# GIO register map
Vendor: Texas Instruments
Peripheral module from a debugger description file (folder ucd3138128).
Registers are 32-bit, access not given, no defined reset value unless marked. A register's access mark holds for its fields unless they carry their own. Offsets are as the file gives them; lines under a group give offsets from that group; [hi:lo] are bit positions; {n}, {i} and the like mark numbered series; 'fields as' and 'values as' point back to an identical list; <NAME> marks a mode.

## GIO
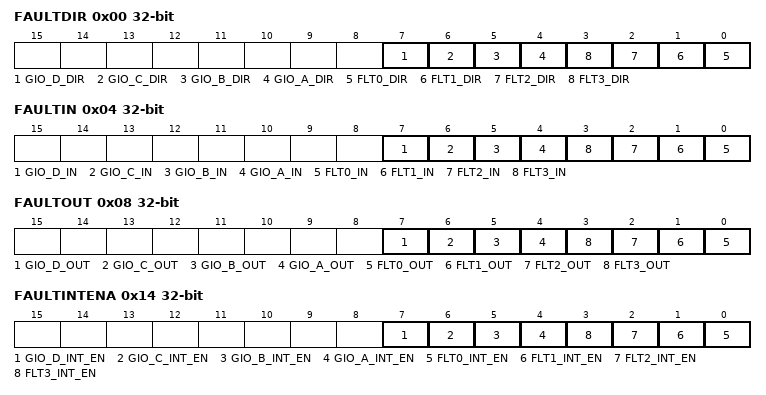
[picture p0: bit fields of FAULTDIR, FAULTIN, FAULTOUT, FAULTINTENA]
0x00 FAULTDIR — Fault Port Direction Register
  [7] GIO_D_DIR rw — GIO_D Pin Direction in GPIO Mode
  [6] GIO_C_DIR rw — GIO_C Pin Direction in GPIO Mode
  [5] GIO_B_DIR rw — GIO_B Pin Direction in GPIO Mode
  [4] GIO_A_DIR rw — GIO_A Pin Direction in GPIO Mode
  [n] FLT{n}_DIR rw (n=0..3) — FAULT[{n}] Pin Direction
0x04 FAULTIN — Fault Port Input Data
  [7] GIO_D_IN ro — GIO_D Input Value in GPIO Mode
  [6] GIO_C_IN ro — GIO_C Input Value in GPIO Mode
  [5] GIO_B_IN ro — GIO_B Input Value in GPIO Mode
  [4] GIO_A_IN ro — GIO_A Input Value in GPIO Mode
  [n] FLT{n}_IN ro (n=0..3) — FAULT[{n}] Input Value
0x08 FAULTOUT — Fault Port Output Data
  [7] GIO_D_OUT rw — GIO_D pin output data
  [6] GIO_C_OUT rw — GIO_C pin output data
  [5] GIO_B_OUT rw — GIO_B pin output data
  [4] GIO_A_OUT rw — GIO_A pin output data
  [n] FLT{n}_OUT rw (n=0..3) — FAULT[{n}] pin output data
0x14 FAULTINTENA — Fault Port Interrupt Enable Register
  [7] GIO_D_INT_EN rw — GIO_D pin interrupt enable
  [6] GIO_C_INT_EN rw — GIO_C pin interrupt enable
  [5] GIO_B_INT_EN rw — GIO_B pin interrupt enable
  [4] GIO_A_INT_EN rw — GIO_A pin interrupt enable
  [n] FLT{n}_INT_EN rw (n=0..3) — FAULT[{n}] pin interrupt enable
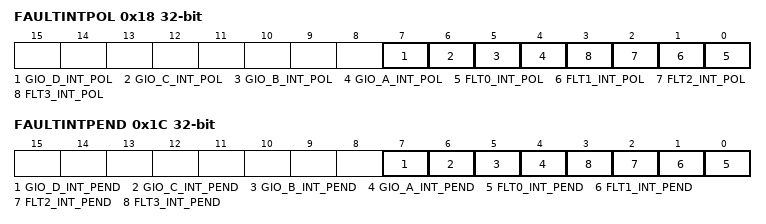
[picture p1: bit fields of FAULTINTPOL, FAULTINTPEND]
0x18 FAULTINTPOL — Fault Port Interrupt Polarity Register
  [7] GIO_D_INT_POL rw — GIO_D pin interrupt polarity
  [6] GIO_C_INT_POL rw — GIO_C pin interrupt polarity
  [5] GIO_B_INT_POL rw — GIO_B pin interrupt polarity
  [4] GIO_A_INT_POL rw — GIO_A pin interrupt polarity
  [n] FLT{n}_INT_POL rw (n=0..3) — FAULT[{n}] pin interrupt polarity
0x1C FAULTINTPEND — Fault Port Interrupt Pending Register
  [7] GIO_D_INT_PEND rw — GIO_D pin interrupt flag
  [6] GIO_C_INT_PEND rw — GIO_C pin interrupt flag
  [5] GIO_B_INT_PEND rw — GIO_B pin interrupt flag
  [4] GIO_A_INT_PEND rw — GIO_A pin interrupt flag
  [n] FLT{n}_INT_PEND rw (n=0..3) — FAULT[{n}] pin interrupt flag
0x20 EXTINTDIR — External Interrupt Direction Register
  [0] EXT_INT_DIR rw — External Interrupt Pin Direction
0x24 EXTINTIN — External Interrupt Input Data
  [0] EXT_INT_IN ro — External Interrupt Pin Input Value
0x28 EXTINTOUT — External Interrupt Output Data
  [0] EXT_INT_OUT rw — External Interrupt pin output data
0x34 EXTINTENA — External Interrupt Enable Register
  [0] EXT_INT_EN rw — External Interrupt pin interrupt enable
0x38 EXTINTPOL — External Interrupt Polarity Register
  [0] EXT_INT_POL rw — External Interrupt pin interrupt polarity
0x3C EXTINTPEND — External Interrupt Pending Register
  [0] EXT_INT_PEND rw — External Interrupt pin interrupt flag
